# RP2350 register map
Vendor: Raspberry Pi; Series: RP; File version: 0.1
Dual Cortex-M33 or Hazard3 processors at 150MHz 520kB on-chip SRAM, in 10 independent banks Extended low-power sleep states with optional SRAM retention: as low as 10uA DVDD 8kB of one-time-programmable storage (OTP) Up to 16MB of external QSPI flash/PSRAM via dedicated QSPI bus Additional 16MB flash/PSRAM accessible via optional second chip-select On-chip switched-mode power supply to generate core voltage Low-quiescent-current LDO mode can be enabled for sleep states 2x on-chip PLLs for internal or external clock generation GPIOs are 5V-tolerant (powered), and 3.3V-failsafe (unpowered) Security features: Optional boot signing, enforced by on-chip mask ROM, with key fingerprint in OTP Protected OTP storage for optional boot decryption key Global bus filtering based on Arm or RISC-V security/privilege levels Peripherals, GPIOs and DMA channels individually assignable to security domains Hardware mitigations for fault injection attacks Hardware SHA-256 accelerator Peripherals: 2x UARTs 2x SPI controllers 2x I2C controllers 24x PWM channels USB 1.1 controller and PHY, with host and device support 12x PIO state machines 1x HSTX peripheral
CPU: CM33 r1p0, little endian, MPU, FPU, DSP, VTOR, 4 interrupt priority bits, 52 interrupts, 8 SAU regions
Registers are 32-bit, read-write, reset 0x116 unless marked. A register's access mark holds for its fields unless they carry their own. Offsets are from the block's base; lines under a group give offsets from that group; [hi:lo] are bit positions; {n}, {i} and the like mark numbered series; 'fields as' and 'values as' point back to an identical list; <NAME> marks a mode.

## Memory map
0x40028000 IO_BANK0 size 0x320
0x40038000 PADS_BANK0 size 0xCC
0xD0000000 SIO size 0x1E8 — Single-cycle IO block Provides core-local and inter-core hardware for the two processors, with single-cycle access.

## PADS_BANK0
Base 0x40038000
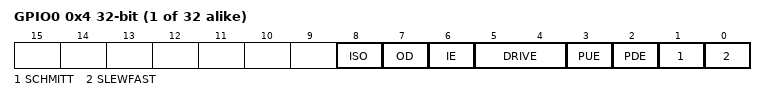
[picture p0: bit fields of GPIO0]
{0x4+4i} GPIO{i} (i=0..31)
  [8] ISO — Pad isolation control. Remove this once the pad is configured by software.
  [7] OD — Output disable. Has priority over output enable from peripherals
  [6] IE — Input enable
  [5:4] DRIVE — Drive strength.
    0=2mA; 1=4mA; 2=8mA; 3=12mA
  [3] PUE — Pull up enable
  [2] PDE — Pull down enable
  [1] SCHMITT — Enable schmitt trigger
  [0] SLEWFAST — Slew rate control. 1 = Fast, 0 = Slow

## SIO — Single-cycle IO block Provides core-local and inter-core hardware for the two processors, with single-cycle access.
Base 0xD0000000
0x04 GPIO_IN reset 0x0 — Input value for GPIO0...31. In the Non-secure SIO, Secure-only GPIOs (as per ACCESSCTRL) appear as zero.
  [31:0] GPIO_IN ro
0x10 GPIO_OUT reset 0x0 — GPIO0...31 output value
  [31:0] GPIO_OUT — Set output level (1/0 -> high/low) for GPIO0...31. Reading back gives the last value written, NOT the input value from the pins. If core 0 and core 1 both write to GPIO_OUT simultaneously (or to a SET/CLR/XOR alias), the result is as though the write from core 0 took place first, and the write from core 1 was then applied to that intermediate result. In the Non-secure SIO, Secure-only GPIOs (as per ACCESSCTRL) ignore writes, and their output status reads back as zero. This is also true for SET/CLR/XOR aliases of this register.
0x18 GPIO_OUT_SET reset 0x0 — GPIO0...31 output value set
  [31:0] GPIO_OUT_SET wo — Perform an atomic bit-set on GPIO_OUT, i.e. `GPIO_OUT |= wdata`
0x20 GPIO_OUT_CLR reset 0x0 — GPIO0...31 output value clear
  [31:0] GPIO_OUT_CLR wo — Perform an atomic bit-clear on GPIO_OUT, i.e. `GPIO_OUT &= ~wdata`
0x28 GPIO_OUT_XOR reset 0x0 — GPIO0...31 output value XOR
  [31:0] GPIO_OUT_XOR wo — Perform an atomic bitwise XOR on GPIO_OUT, i.e. `GPIO_OUT ^= wdata`
0x30 GPIO_OE reset 0x0 — GPIO0...31 output enable
  [31:0] GPIO_OE — Set output enable (1/0 -> output/input) for GPIO0...31. Reading back gives the last value written. If core 0 and core 1 both write to GPIO_OE simultaneously (or to a SET/CLR/XOR alias), the result is as though the write from core 0 took place first, and the write from core 1 was then applied to that intermediate result. In the Non-secure SIO, Secure-only GPIOs (as per ACCESSCTRL) ignore writes, and their output status reads back as zero. This is also true for SET/CLR/XOR aliases of this register.
0x38 GPIO_OE_SET reset 0x0 — GPIO0...31 output enable set
  [31:0] GPIO_OE_SET wo — Perform an atomic bit-set on GPIO_OE, i.e. `GPIO_OE |= wdata`
0x40 GPIO_OE_CLR reset 0x0 — GPIO0...31 output enable clear
  [31:0] GPIO_OE_CLR wo — Perform an atomic bit-clear on GPIO_OE, i.e. `GPIO_OE &= ~wdata`
0x48 GPIO_OE_XOR reset 0x0 — GPIO0...31 output enable XOR
  [31:0] GPIO_OE_XOR wo — Perform an atomic bitwise XOR on GPIO_OE, i.e. `GPIO_OE ^= wdata`

## Licence text in the file
Copyright (c) 2024 Raspberry Pi Ltd. SPDX-License-Identifier: BSD-3-Clause
